# f280015x_dcsm_z1_regs register map
Vendor: Texas Instruments
Peripheral module from a debugger description file (folder C2000).
Address unit: 16 bits
Registers are 32-bit, read-only, no defined reset value unless marked. A register's access mark holds for its fields unless they carry their own. Offsets are as the file gives them; lines under a group give offsets from that group; [hi:lo] are bit positions; {n}, {i} and the like mark numbered series; 'fields as' and 'values as' point back to an identical list; <NAME> marks a mode.

## DCSM_Z1_REGS — DCSM Z1 Registers
0x00 Z1_LINKPOINTER — Zone 1 Link Pointer
  [13:0] LINKPOINTER — Zone1 LINK Pointer
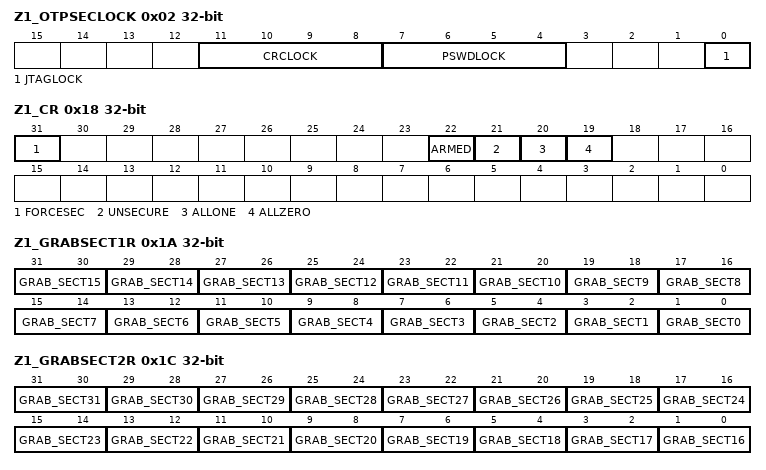
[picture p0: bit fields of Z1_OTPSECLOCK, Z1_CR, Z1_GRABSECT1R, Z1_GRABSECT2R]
0x02 Z1_OTPSECLOCK — Zone 1 OTP Secure Lock
  [11:8] CRCLOCK — Zone1 CRC Lock.
  [7:4] PSWDLOCK — Zone1 Password Lock.
  [0] JTAGLOCK — JTAG Lock Status
0x04 Z1_JLM_ENABLE — Zone 1 JTAGLOCK Enable Register
  [3:0] Z1_JLM_ENABLE — Zone1 JLM_ENABLE register.
0x06 Z1_LINKPOINTERERR — Link Pointer Error
  [13:0] Z1_LINKPOINTERERR — Error to Resolve Z1 Link pointer from OTP loaded values
{0x6+2i} Z1_GPREG{i} (i=1..4) — Zone 1 General Purpose Register-{i}
  [31:0] GPREG{i} — General Purpose Register-{i}
0x10 Z1_CSMKEY0 rw — Zone 1 CSM Key 0
  [31:0] Z1_CSMKEY0 — Word0 to unlock Zone1, should match Z1_CSMPSWD0.
{0x10+2i} Z1_CSMKEY{i} rw (i=1..3) — Zone 1 CSM Key {i}
  [31:0] Z1_CSMKEY{i} — Word{i} to unlock Zone1, should match Z1_CSMPSWD{i}
0x18 Z1_CR access per field — Zone 1 CSM Control Register
  [31] FORCESEC rw — Force Secure
  [22] ARMED ro — CSM Passwords Read Status
  [21] UNSECURE ro — CSMPSWD Match CSMKEY
  [20] ALLONE ro — CSMPSWD All Ones
  [19] ALLZERO ro — CSMPSWD All Zeros
0x1A Z1_GRABSECT1R — Zone 1 Grab Flash Status Register 1
  [2n+1:2n] GRAB_SECT{n} (n=0..15) — Grab Flash Sector {n}
0x1C Z1_GRABSECT2R — Zone 1 Grab Flash Status Register 2
  [2n-31:2n-32] GRAB_SECT{n} (n=16..31) — Grab Flash Sector {n}
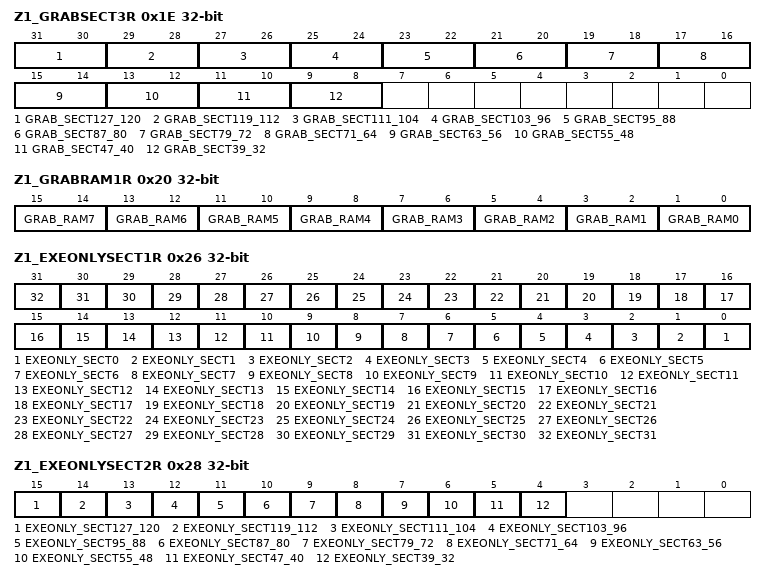
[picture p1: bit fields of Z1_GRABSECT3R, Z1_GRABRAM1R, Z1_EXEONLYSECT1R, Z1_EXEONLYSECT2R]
0x1E Z1_GRABSECT3R — Zone 1 Grab Flash Status Register 3
  [31:30] GRAB_SECT127_120 — Grab Flash Sectors 127-120
  [29:28] GRAB_SECT119_112 — Grab Flash Sectors 119-112
  [27:26] GRAB_SECT111_104 — Grab Flash Sectors 111_104
  [25:24] GRAB_SECT103_96 — Grab Flash Sectors 103-96
  [23:22] GRAB_SECT95_88 — Grab Flash Sectors 95-88
  [21:20] GRAB_SECT87_80 — Grab Flash Sectors 87-80
  [19:18] GRAB_SECT79_72 — Grab Flash Sectors 79-72
  [17:16] GRAB_SECT71_64 — Grab Flash Sectors 71_64
  [15:14] GRAB_SECT63_56 — Grab Flash Sectors 63-56
  [13:12] GRAB_SECT55_48 — Grab Flash Sectors 55-48
  [11:10] GRAB_SECT47_40 — Grab Flash Sectors 47-40
  [9:8] GRAB_SECT39_32 — Grab Flash Sectors 39-32
0x20 Z1_GRABRAM1R — Zone 1 Grab RAM Status Register 1
  [15:14] GRAB_RAM7 — Grab RAM LS1 Section D
  [13:12] GRAB_RAM6 — Grab RAM LS1 Section C
  [11:10] GRAB_RAM5 — Grab RAM LS1 Section B
  [9:8] GRAB_RAM4 — Grab RAM LS1 Section A
  [7:6] GRAB_RAM3 — Grab RAM LS0 Section D
  [5:4] GRAB_RAM2 — Grab RAM LS0 Section C
  [3:2] GRAB_RAM1 — Grab RAM LS0 Section B
  [1:0] GRAB_RAM0 — Grab RAM LS0 Section A
0x26 Z1_EXEONLYSECT1R — Zone 1 Execute Only Flash Status Register 1
  [n] EXEONLY_SECT{n} (n=0..31) — Execute-Only Flash Sector {n}
0x28 Z1_EXEONLYSECT2R — Zone 1 Execute Only Flash Status Register 2
  [15] EXEONLY_SECT127_120 — Execute-Only Flash Sectors 127-120
  [14] EXEONLY_SECT119_112 — Execute-Only Flash Sectors 119-112
  [13] EXEONLY_SECT111_104 — Execute-Only Flash Sectors 111-104
  [12] EXEONLY_SECT103_96 — Execute-Only Flash Sectors 103-96
  [11] EXEONLY_SECT95_88 — Execute-Only Flash Sectors 95-88
  [10] EXEONLY_SECT87_80 — Execute-Only Flash Sectors 87-80
  [9] EXEONLY_SECT79_72 — Execute-Only Flash Sectors 79-72
  [8] EXEONLY_SECT71_64 — Execute-Only Flash Sectors 71-64
  [7] EXEONLY_SECT63_56 — Execute-Only Flash Sectors 63-56
  [6] EXEONLY_SECT55_48 — Execute-Only Flash Sectors 55-48
  [5] EXEONLY_SECT47_40 — Execute-Only Flash Sectors 47-40
  [4] EXEONLY_SECT39_32 — Execute-Only Flash Sectors 39_32
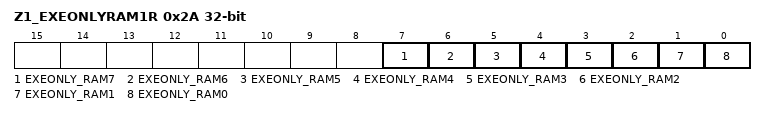
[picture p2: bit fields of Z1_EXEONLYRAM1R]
0x2A Z1_EXEONLYRAM1R — Zone 1 Execute Only RAM Status Register 1
  [7] EXEONLY_RAM7 — Execute-Only RAM LS1 Section D
  [6] EXEONLY_RAM6 — Execute-Only RAM LS1 Section C
  [5] EXEONLY_RAM5 — Execute-Only RAM LS1 Section B
  [4] EXEONLY_RAM4 — Execute-Only RAM LS1 Section A
  [3] EXEONLY_RAM3 — Execute-Only RAM LS0 Section D
  [2] EXEONLY_RAM2 — Execute-Only RAM LS0 Section C
  [1] EXEONLY_RAM1 — Execute-Only RAM LS0 Section B
  [0] EXEONLY_RAM0 — Execute-Only RAM LS0 Section A
{0x2E+2i} Z1_JTAGKEY{i} (i=0..3) — JTAG Unlock Key Register {i}
  [31:0] KEY{i} — JTAGKEY Bits {32i+31}:{32i}
{0x36+2i} Z1_CMACKEY{i} (i=0..3) — Secure Boot CMAC Key Status Register {i}
  [31:0] KEY{i} — CMACKEY Bits {32i+31}:{32i}
